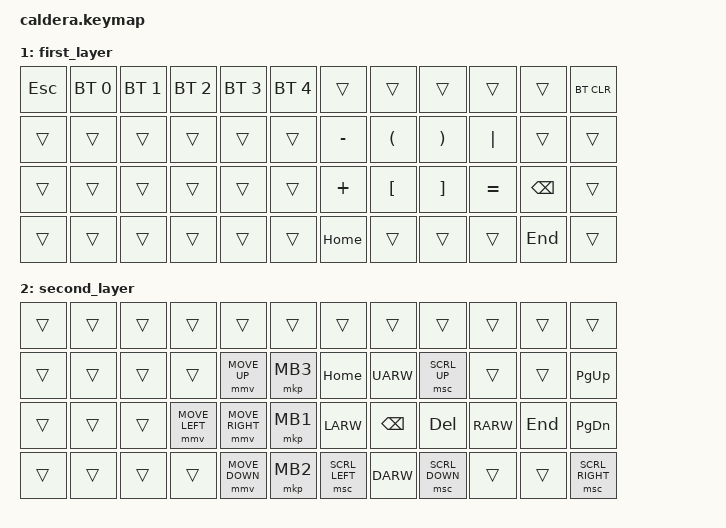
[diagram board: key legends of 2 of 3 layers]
// #define ZMK_POINTING_DEFAULT_MOVE_VAL 800  // default: 600
// #define ZMK_POINTING_DEFAULT_SCRL_VAL 20    // default: 10

#include <behaviors.dtsi>
#include <dt-bindings/zmk/keys.h>
#include <dt-bindings/zmk/bt.h>
#include <dt-bindings/zmk/pointing.h>

/ {
        keymap {
                compatible = "zmk,keymap";

                default_layer {
// ---------------------------------------------------------------------------------
// |   `  |  1  |  2  |  3  |  4  |  5  |     |  6  |  7  |  8  |  9  |  0  | BKSP |
// |  TAB |  Q  |  W  |  E  |  R  |  T  |     |  Y  |  U  |  I  |  O  |  P  |  \   |
// | CAPS |  A  |  S  |  D  |  F  |  G  |     |  H  |  J  |  K  |  L  |  ;  |  ENT |
// | SHFT |  Z  |  X  |  C  |  V  |  B  |     |  N  |  M  |  ,  |  .  |  /  | APOS |
// | CTRL | ALT | GUI | SPC | SPC | SPC |     | SPC | LOW |LARW |DARW |UARW | RARW |
                        bindings = <
   &mt GRAVE ESC  &kp N1    &kp N2    &kp N3     &kp N4     &kp N5               &kp N6         &kp N7  &kp N8     &kp N9    &kp N0    &kp BSPC
   &kp TAB    &kp Q     &kp W     &kp E      &kp R      &kp T                &kp Y          &kp U   &kp I      &kp O     &kp P     &kp BSLH
   &kp CAPS   &kp A     &kp S     &kp D      &kp F      &kp G                &kp H          &kp J   &kp K      &kp L     &kp SEMI  &kp RET
   &kp LSHFT  &kp Z     &kp X     &kp C      &kp V      &kp B                &kp N          &kp M   &kp COMMA  &kp DOT   &kp FSLH  &kp APOS
   &kp LCTRL  &kp LALT  &kp LGUI  &kp SPACE  &kp LALT   &kp LGUI             &lt 2 SPACE    &mo 1   &kp LARW   &kp DARW  &kp UARW  &kp RARW
                        >;
                };
                first_layer {
                        bindings = <
   &kp ESC   &bt BT_SEL 0   &bt BT_SEL 1   &bt BT_SEL 2   &bt BT_SEL 3   &bt BT_SEL 4           &trans      &trans      &trans     &trans      &trans      &bt BT_CLR
   &trans    &trans         &trans         &trans         &trans         &trans                 &kp MINUS   &kp LPAR    &kp RPAR   &kp PIPE      &trans      &trans
   &trans    &trans         &trans         &trans         &trans         &trans                 &kp PLUS    &kp LBKT    &kp RBKT   &kp EQUAL   &kp BKSP    &trans
   &trans    &trans         &trans         &trans         &trans         &trans                 &kp HOME    &trans      &trans     &trans        &kp END      &trans
                        >;
                };
                second_layer {
                        bindings = <
        &trans      &trans           &trans           &trans         &trans            &trans               &trans           &trans        &trans              &trans        &trans           &trans
        &trans      &trans           &trans           &trans         &mmv MOVE_UP      &mkp MB3             &kp HOME         &kp UARW      &msc SCRL_UP        &trans        &trans           &kp PG_UP
        &trans      &trans           &trans           &mmv MOVE_LEFT &mmv MOVE_RIGHT   &mkp MB1             &kp LARW         &kp BSPC      &kp DEL             &kp RARW      &kp END          &kp PG_DN
        &trans      &trans           &trans           &trans         &mmv MOVE_DOWN    &mkp MB2             &msc SCRL_LEFT   &kp DARW      &msc SCRL_DOWN      &trans        &trans           &msc SCRL_RIGHT
                        >;
                };
        };
};

// Completed second layer switch on space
